AUTOSAR XML (schema 4-2-2)
package /STELLANTIS/EPT/SASWCs
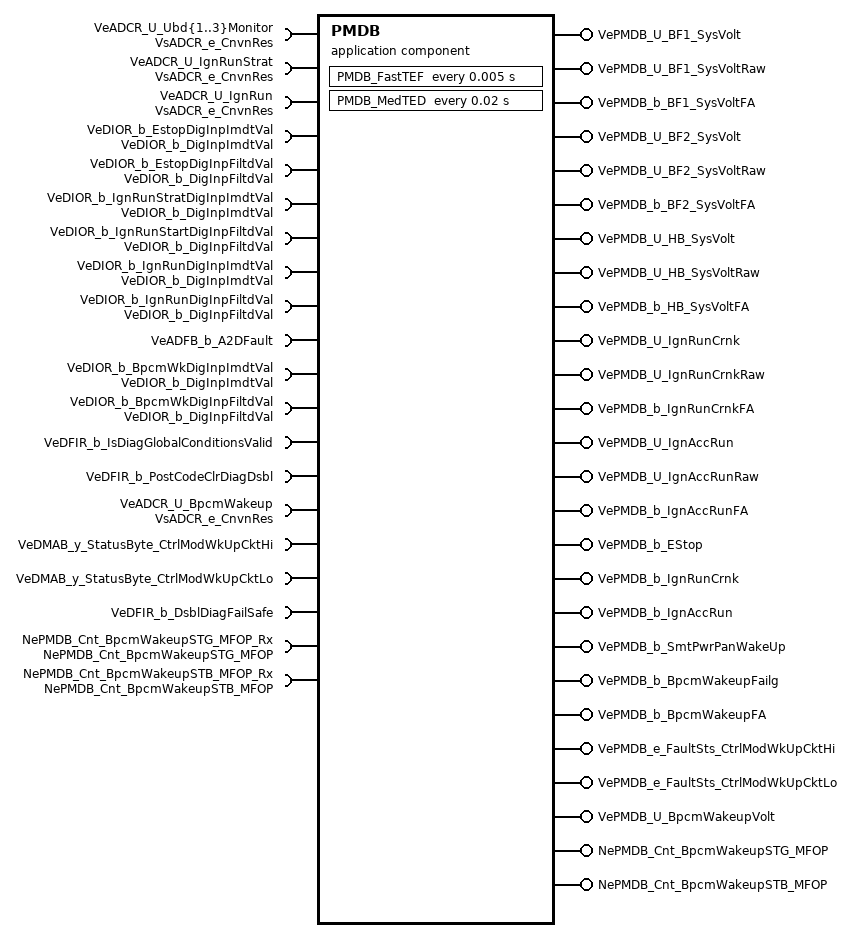
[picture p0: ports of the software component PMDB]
  application sw component type PMDB
    20 x require port:
      VeADCR_U_Ubd{1..3}Monitor: variation-point={short-label=vpVeADCR_U_Ubd{1..3}Monitor, sw-syscond=1}, nonqueued-receiver-com-spec{data-element=VsADCR_e_CnvnRes, init-value={short-label=DefaultInitValue_IDTRAdcInpResData, fields=[0, 0]}}, required-interface=VsADCR_e_CnvnRes
      VeADCR_U_IgnRunStrat: variation-point={short-label=vpVeADCR_U_IgnRunStrat, sw-syscond=1}, nonqueued-receiver-com-spec{data-element=VsADCR_e_CnvnRes, init-value={short-label=DefaultInitValue_IDTRAdcInpResData, fields=[0, 0]}}, required-interface=VsADCR_e_CnvnRes
      VeADCR_U_IgnRun: variation-point={short-label=vpVeADCR_U_IgnRun, sw-syscond=1}, nonqueued-receiver-com-spec{data-element=VsADCR_e_CnvnRes, init-value={short-label=DefaultInitValue_IDTRAdcInpResData, fields=[0, 0]}}, required-interface=VsADCR_e_CnvnRes
      VeDIOR_b_EstopDigInpImdtVal: variation-point={short-label=vpVeDIOR_b_EstopDigInpImdtVal, sw-syscond=1}, nonqueued-receiver-com-spec{data-element=VeDIOR_b_DigInpImdtVal, init-value=0}, required-interface=VeDIOR_b_DigInpImdtVal
      VeDIOR_b_EstopDigInpFiltdVal: variation-point={short-label=vpVeDIOR_b_EstopDigInpFiltdVal, sw-syscond=1}, nonqueued-receiver-com-spec{data-element=VeDIOR_b_DigInpFiltdVal, init-value=0}, required-interface=VeDIOR_b_DigInpFiltdVal
      VeDIOR_b_IgnRunStratDigInpImdtVal: variation-point={short-label=vpVeDIOR_b_IgnRunStratDigInpImdtVal, sw-syscond=1}, nonqueued-receiver-com-spec{data-element=VeDIOR_b_DigInpImdtVal, init-value=0}, required-interface=VeDIOR_b_DigInpImdtVal
      VeDIOR_b_IgnRunStartDigInpFiltdVal: variation-point={short-label=vpVeDIOR_b_IgnRunStartDigInpFiltdVal, sw-syscond=1}, nonqueued-receiver-com-spec{data-element=VeDIOR_b_DigInpFiltdVal, init-value=0}, required-interface=VeDIOR_b_DigInpFiltdVal
      VeDIOR_b_IgnRunDigInpImdtVal: variation-point={short-label=vpVeDIOR_b_IgnRunDigInpImdtVal, sw-syscond=1}, nonqueued-receiver-com-spec{data-element=VeDIOR_b_DigInpImdtVal, init-value=0}, required-interface=VeDIOR_b_DigInpImdtVal
      VeDIOR_b_IgnRunDigInpFiltdVal: variation-point={short-label=vpVeDIOR_b_IgnRunDigInpFiltdVal, sw-syscond=1}, nonqueued-receiver-com-spec{data-element=VeDIOR_b_DigInpFiltdVal, init-value=0}, required-interface=VeDIOR_b_DigInpFiltdVal
      VeADFB_b_A2DFault: variation-point={short-label=vpVeADFB_b_A2DFault, sw-syscond=1}, nonqueued-receiver-com-spec{data-element=Value, init-value=0}, required-interface=VeADFB_b_A2DFault
      VeDIOR_b_BpcmWkDigInpImdtVal: variation-point={short-label=vpVeDIOR_b_BpcmWkDigInpImdtVal, sw-syscond=1}, nonqueued-receiver-com-spec{data-element=VeDIOR_b_DigInpImdtVal, init-value=0}, required-interface=VeDIOR_b_DigInpImdtVal
      VeDIOR_b_BpcmWkDigInpFiltdVal: variation-point={short-label=vpVeDIOR_b_BpcmWkDigInpFiltdVal, sw-syscond=1}, nonqueued-receiver-com-spec{data-element=VeDIOR_b_DigInpFiltdVal, init-value=0}, required-interface=VeDIOR_b_DigInpFiltdVal
      VeDFIR_b_IsDiagGlobalConditionsValid: variation-point={short-label=vpVeDFIR_b_IsDiagGlobalConditionsValid, sw-syscond=1}, nonqueued-receiver-com-spec{data-element=Value, init-value=0}, required-interface=VeDFIR_b_IsDiagGlobalConditionsValid
      VeDFIR_b_PostCodeClrDiagDsbl: variation-point={short-label=vpVeDFIR_b_PostCodeClrDiagDsbl, sw-syscond=1}, nonqueued-receiver-com-spec{data-element=Value, init-value=0}, required-interface=VeDFIR_b_PostCodeClrDiagDsbl
      VeADCR_U_BpcmWakeup: variation-point={short-label=vpVeADCR_U_BpcmWakeup, sw-syscond=1}, nonqueued-receiver-com-spec{data-element=VsADCR_e_CnvnRes, init-value={short-label=DefaultInitValue_IDTRAdcInpResData, fields=[0, 0]}}, required-interface=VsADCR_e_CnvnRes
      VeDMAB_y_StatusByte_CtrlModWkUpCktHi: variation-point={short-label=vpVeDMAB_y_StatusByte_CtrlModWkUpCktHi, sw-syscond=1}, nonqueued-receiver-com-spec{data-element=Value, init-value=0}, required-interface=VeDMAB_y_StatusByte_CtrlModWkUpCktHi
      VeDMAB_y_StatusByte_CtrlModWkUpCktLo: variation-point={short-label=vpVeDMAB_y_StatusByte_CtrlModWkUpCktLo, sw-syscond=1}, nonqueued-receiver-com-spec{data-element=Value, init-value=0}, required-interface=VeDMAB_y_StatusByte_CtrlModWkUpCktLo
      VeDFIR_b_DsblDiagFailSafe: variation-point={short-label=vpVeDFIR_b_DsblDiagFailSafe, sw-syscond=1}, nonqueued-receiver-com-spec{data-element=Value, init-value=0}, required-interface=VeDFIR_b_DsblDiagFailSafe
    24 x provide port:
      VePMDB_U_BF1_SysVolt: variation-point={short-label=vpVePMDB_U_BF1_SysVolt, sw-syscond=1}, nonqueued-sender-com-spec{data-element=Value, init-value=0}, provided-interface=VePMDB_U_BF1_SysVolt
      VePMDB_U_BF1_SysVoltRaw: variation-point={short-label=vpVePMDB_U_BF1_SysVoltRaw, sw-syscond=1}, nonqueued-sender-com-spec{data-element=Value, init-value=0}, provided-interface=VePMDB_U_BF1_SysVoltRaw
      VePMDB_b_BF1_SysVoltFA: variation-point={short-label=vpVePMDB_b_BF1_SysVoltFA, sw-syscond=1}, nonqueued-sender-com-spec{data-element=Value, init-value=0}, provided-interface=VePMDB_b_BF1_SysVoltFA
      VePMDB_U_BF2_SysVolt: variation-point={short-label=vpVePMDB_U_BF2_SysVolt, sw-syscond=1}, nonqueued-sender-com-spec{data-element=Value, init-value=0}, provided-interface=VePMDB_U_BF2_SysVolt
      VePMDB_U_BF2_SysVoltRaw: variation-point={short-label=vpVePMDB_U_BF2_SysVoltRaw, sw-syscond=1}, nonqueued-sender-com-spec{data-element=Value, init-value=0}, provided-interface=VePMDB_U_BF2_SysVoltRaw
      VePMDB_b_BF2_SysVoltFA: variation-point={short-label=vpVePMDB_b_BF2_SysVoltFA, sw-syscond=1}, nonqueued-sender-com-spec{data-element=Value, init-value=0}, provided-interface=VePMDB_b_BF2_SysVoltFA
      VePMDB_U_HB_SysVolt: variation-point={short-label=vpVePMDB_U_HB_SysVolt, sw-syscond=1}, nonqueued-sender-com-spec{data-element=Value, init-value=0}, provided-interface=VePMDB_U_HB_SysVolt
      VePMDB_U_HB_SysVoltRaw: variation-point={short-label=vpVePMDB_U_HB_SysVoltRaw, sw-syscond=1}, nonqueued-sender-com-spec{data-element=Value, init-value=0}, provided-interface=VePMDB_U_HB_SysVoltRaw
      VePMDB_b_HB_SysVoltFA: variation-point={short-label=vpVePMDB_b_HB_SysVoltFA, sw-syscond=1}, nonqueued-sender-com-spec{data-element=Value, init-value=0}, provided-interface=VePMDB_b_HB_SysVoltFA
      VePMDB_U_IgnRunCrnk: variation-point={short-label=vpVePMDB_U_IgnRunCrnk, sw-syscond=1}, nonqueued-sender-com-spec{data-element=Value, init-value=0}, provided-interface=VePMDB_U_IgnRunCrnk
      VePMDB_U_IgnRunCrnkRaw: variation-point={short-label=vpVePMDB_U_IgnRunCrnkRaw, sw-syscond=1}, nonqueued-sender-com-spec{data-element=Value, init-value=0}, provided-interface=VePMDB_U_IgnRunCrnkRaw
      VePMDB_b_IgnRunCrnkFA: variation-point={short-label=vpVePMDB_b_IgnRunCrnkFA, sw-syscond=1}, nonqueued-sender-com-spec{data-element=Value, init-value=0}, provided-interface=VePMDB_b_IgnRunCrnkFA
      VePMDB_U_IgnAccRun: variation-point={short-label=vpVePMDB_U_IgnAccRun, sw-syscond=1}, nonqueued-sender-com-spec{data-element=Value, init-value=0}, provided-interface=VePMDB_U_IgnAccRun
      VePMDB_U_IgnAccRunRaw: variation-point={short-label=vpVePMDB_U_IgnAccRunRaw, sw-syscond=1}, nonqueued-sender-com-spec{data-element=Value, init-value=0}, provided-interface=VePMDB_U_IgnAccRunRaw
      VePMDB_b_IgnAccRunFA: variation-point={short-label=vpVePMDB_b_IgnAccRunFA, sw-syscond=1}, nonqueued-sender-com-spec{data-element=Value, init-value=0}, provided-interface=VePMDB_b_IgnAccRunFA
      VePMDB_b_EStop: variation-point={short-label=vpVePMDB_b_EStop, sw-syscond=1}, nonqueued-sender-com-spec{data-element=Value, init-value=0}, provided-interface=VePMDB_b_EStop
      VePMDB_b_IgnRunCrnk: variation-point={short-label=vpVePMDB_b_IgnRunCrnk, sw-syscond=1}, nonqueued-sender-com-spec{data-element=Value, init-value=0}, provided-interface=VePMDB_b_IgnRunCrnk
      VePMDB_b_IgnAccRun: variation-point={short-label=vpVePMDB_b_IgnAccRun, sw-syscond=1}, nonqueued-sender-com-spec{data-element=Value, init-value=0}, provided-interface=VePMDB_b_IgnAccRun
      VePMDB_b_SmtPwrPanWakeUp: variation-point={short-label=vpVePMDB_b_SmtPwrPanWakeUp, sw-syscond=1}, nonqueued-sender-com-spec{data-element=Value, init-value=0}, provided-interface=VePMDB_b_SmtPwrPanWakeUp
      VePMDB_b_BpcmWakeupFailg: variation-point={short-label=vpVePMDB_b_BpcmWakeupFailg, sw-syscond=1}, nonqueued-sender-com-spec{data-element=Value, init-value=0}, provided-interface=VePMDB_b_BpcmWakeupFailg
      VePMDB_b_BpcmWakeupFA: variation-point={short-label=vpVePMDB_b_BpcmWakeupFA, sw-syscond=1}, nonqueued-sender-com-spec{data-element=Value, init-value=0}, provided-interface=VePMDB_b_BpcmWakeupFA
      VePMDB_e_FaultSts_CtrlModWkUpCktHi: variation-point={short-label=vpVePMDB_e_FaultSts_CtrlModWkUpCktHi, sw-syscond=1}, nonqueued-sender-com-spec{data-element=Value, init-value=CeDFIB_e_Init}, provided-interface=VePMDB_e_FaultSts_CtrlModWkUpCktHi
      VePMDB_e_FaultSts_CtrlModWkUpCktLo: variation-point={short-label=vpVePMDB_e_FaultSts_CtrlModWkUpCktLo, sw-syscond=1}, nonqueued-sender-com-spec{data-element=Value, init-value=CeDFIB_e_Init}, provided-interface=VePMDB_e_FaultSts_CtrlModWkUpCktLo
      VePMDB_U_BpcmWakeupVolt: variation-point={short-label=vpVePMDB_U_BpcmWakeupVolt, sw-syscond=1}, nonqueued-sender-com-spec{data-element=Value, init-value=0}, provided-interface=VePMDB_U_BpcmWakeupVolt
    require port NePMDB_Cnt_BpcmWakeupSTG_MFOP_Rx: variation-point={short-label=vpNePMDB_Cnt_BpcmWakeupSTG_MFOP_Rx, sw-syscond=1}, nv-require-com-spec{init-value=0, variable=NePMDB_Cnt_BpcmWakeupSTG_MFOP}, required-interface=NePMDB_Cnt_BpcmWakeupSTG_MFOP
    require port NePMDB_Cnt_BpcmWakeupSTB_MFOP_Rx: variation-point={short-label=vpNePMDB_Cnt_BpcmWakeupSTB_MFOP_Rx, sw-syscond=1}, nv-require-com-spec{init-value=0, variable=NePMDB_Cnt_BpcmWakeupSTB_MFOP}, required-interface=NePMDB_Cnt_BpcmWakeupSTB_MFOP
    provide port NePMDB_Cnt_BpcmWakeupSTG_MFOP: nv-provide-com-spec{ram-block-init-value=0, variable=NePMDB_Cnt_BpcmWakeupSTG_MFOP}, provided-interface=NePMDB_Cnt_BpcmWakeupSTG_MFOP
    provide port NePMDB_Cnt_BpcmWakeupSTB_MFOP: nv-provide-com-spec{ram-block-init-value=0, variable=NePMDB_Cnt_BpcmWakeupSTB_MFOP}, provided-interface=NePMDB_Cnt_BpcmWakeupSTB_MFOP
    behavior IB_PMDB: data-type-mapping=[msADTtoIDTMapping, ADTtoIDTMapping], handle-termination-and-restart=NO-SUPPORT
      timing event Event_FastTEF: start-on-event=PMDB_FastTEF, period=0.005
      timing event Event_MedTED: start-on-event=PMDB_MedTED, period=0.02
      init event Event_PMDB_ac_Init: start-on-event=PMDB_ac_Init
      init event Event_PwrOff: start-on-event=PMDB_PwrOff
      4 x runnable:
        PMDB_ac_Init
          data-receive-point-by-arguments:
            access IN_NePMDB_Cnt_BpcmWakeupSTB_MFOP_Rx_NePMDB_Cnt_BpcmWakeupSTB_MFOP: accessed-variable=NePMDB_Cnt_BpcmWakeupSTB_MFOP_Rx.NePMDB_Cnt_BpcmWakeupSTB_MFOP, variation-point={short-label=vpIN_NePMDB_Cnt_BpcmWakeupSTB_MFOP_Rx_NePMDB_Cnt_BpcmWakeupSTB_MFOP, sw-syscond=1}
            access IN_NePMDB_Cnt_BpcmWakeupSTG_MFOP_Rx_NePMDB_Cnt_BpcmWakeupSTG_MFOP: accessed-variable=NePMDB_Cnt_BpcmWakeupSTG_MFOP_Rx.NePMDB_Cnt_BpcmWakeupSTG_MFOP, variation-point={short-label=vpIN_NePMDB_Cnt_BpcmWakeupSTG_MFOP_Rx_NePMDB_Cnt_BpcmWakeupSTG_MFOP, sw-syscond=1}
          data-send-points:
            19 x access:
              OUT_VePMDB_U_BF1_SysVolt_Value: accessed-variable=VePMDB_U_BF1_SysVolt.Value, variation-point={short-label=vpOUT_VePMDB_U_BF1_SysVolt_Value, sw-syscond=1}
              OUT_VePMDB_U_BF1_SysVoltRaw_Value: accessed-variable=VePMDB_U_BF1_SysVoltRaw.Value, variation-point={short-label=vpOUT_VePMDB_U_BF1_SysVoltRaw_Value, sw-syscond=1}
              OUT_VePMDB_U_BF2_SysVolt_Value: accessed-variable=VePMDB_U_BF2_SysVolt.Value, variation-point={short-label=vpOUT_VePMDB_U_BF2_SysVolt_Value, sw-syscond=1}
              OUT_VePMDB_U_BF2_SysVoltRaw_Value: accessed-variable=VePMDB_U_BF2_SysVoltRaw.Value, variation-point={short-label=vpOUT_VePMDB_U_BF2_SysVoltRaw_Value, sw-syscond=1}
              OUT_VePMDB_U_HB_SysVolt_Value: accessed-variable=VePMDB_U_HB_SysVolt.Value, variation-point={short-label=vpOUT_VePMDB_U_HB_SysVolt_Value, sw-syscond=1}
              OUT_VePMDB_U_HB_SysVoltRaw_Value: accessed-variable=VePMDB_U_HB_SysVoltRaw.Value, variation-point={short-label=vpOUT_VePMDB_U_HB_SysVoltRaw_Value, sw-syscond=1}
              OUT_VePMDB_U_IgnRunCrnk_Value: accessed-variable=VePMDB_U_IgnRunCrnk.Value, variation-point={short-label=vpOUT_VePMDB_U_IgnRunCrnk_Value, sw-syscond=1}
              OUT_VePMDB_U_IgnRunCrnkRaw_Value: accessed-variable=VePMDB_U_IgnRunCrnkRaw.Value, variation-point={short-label=vpOUT_VePMDB_U_IgnRunCrnkRaw_Value, sw-syscond=1}
              OUT_VePMDB_U_IgnAccRun_Value: accessed-variable=VePMDB_U_IgnAccRun.Value, variation-point={short-label=vpOUT_VePMDB_U_IgnAccRun_Value, sw-syscond=1}
              OUT_VePMDB_U_IgnAccRunRaw_Value: accessed-variable=VePMDB_U_IgnAccRunRaw.Value, variation-point={short-label=vpOUT_VePMDB_U_IgnAccRunRaw_Value, sw-syscond=1}
              OUT_VePMDB_b_EStop_Value: accessed-variable=VePMDB_b_EStop.Value, variation-point={short-label=vpOUT_VePMDB_b_EStop_Value, sw-syscond=1}
              OUT_VePMDB_b_IgnRunCrnk_Value: accessed-variable=VePMDB_b_IgnRunCrnk.Value, variation-point={short-label=vpOUT_VePMDB_b_IgnRunCrnk_Value, sw-syscond=1}
              OUT_VePMDB_b_IgnAccRun_Value: accessed-variable=VePMDB_b_IgnAccRun.Value, variation-point={short-label=vpOUT_VePMDB_b_IgnAccRun_Value, sw-syscond=1}
              OUT_VePMDB_b_SmtPwrPanWakeUp_Value: accessed-variable=VePMDB_b_SmtPwrPanWakeUp.Value, variation-point={short-label=vpOUT_VePMDB_b_SmtPwrPanWakeUp_Value, sw-syscond=1}
              OUT_VePMDB_b_BpcmWakeupFailg_Value: accessed-variable=VePMDB_b_BpcmWakeupFailg.Value, variation-point={short-label=vpOUT_VePMDB_b_BpcmWakeupFailg_Value, sw-syscond=1}
              OUT_VePMDB_b_BpcmWakeupFA_Value: accessed-variable=VePMDB_b_BpcmWakeupFA.Value, variation-point={short-label=vpOUT_VePMDB_b_BpcmWakeupFA_Value, sw-syscond=1}
              OUT_VePMDB_e_FaultSts_CtrlModWkUpCktHi_Value: accessed-variable=VePMDB_e_FaultSts_CtrlModWkUpCktHi.Value, variation-point={short-label=vpOUT_VePMDB_e_FaultSts_CtrlModWkUpCktHi_Value, sw-syscond=1}
              OUT_VePMDB_e_FaultSts_CtrlModWkUpCktLo_Value: accessed-variable=VePMDB_e_FaultSts_CtrlModWkUpCktLo.Value, variation-point={short-label=vpOUT_VePMDB_e_FaultSts_CtrlModWkUpCktLo_Value, sw-syscond=1}
              OUT_VePMDB_U_BpcmWakeupVolt_Value: accessed-variable=VePMDB_U_BpcmWakeupVolt.Value, variation-point={short-label=vpOUT_VePMDB_U_BpcmWakeupVolt_Value, sw-syscond=1}
        PMDB_FastTEF
          data-receive-point-by-arguments:
            20 x access:
              IN_VeADCR_U_BpcmWakeup_VsADCR_e_CnvnRes: accessed-variable=VeADCR_U_BpcmWakeup.VsADCR_e_CnvnRes, variation-point={short-label=vpIN_VeADCR_U_BpcmWakeup_VsADCR_e_CnvnRes, sw-syscond=1}
              IN_VeADCR_U_IgnRunStrat_VsADCR_e_CnvnRes: accessed-variable=VeADCR_U_IgnRunStrat.VsADCR_e_CnvnRes, variation-point={short-label=vpIN_VeADCR_U_IgnRunStrat_VsADCR_e_CnvnRes, sw-syscond=1}
              IN_VeADCR_U_IgnRun_VsADCR_e_CnvnRes: accessed-variable=VeADCR_U_IgnRun.VsADCR_e_CnvnRes, variation-point={short-label=vpIN_VeADCR_U_IgnRun_VsADCR_e_CnvnRes, sw-syscond=1}
              IN_VeADCR_U_Ubd{1..3}Monitor_VsADCR_e_CnvnRes: accessed-variable=VeADCR_U_Ubd{1..3}Monitor.VsADCR_e_CnvnRes, variation-point={short-label=vpIN_VeADCR_U_Ubd{1..3}Monitor_VsADCR_e_CnvnRes, sw-syscond=1}
              IN_VeADFB_b_A2DFault_Value: accessed-variable=VeADFB_b_A2DFault.Value, variation-point={short-label=vpIN_VeADFB_b_A2DFault_Value, sw-syscond=1}
              IN_VeDFIR_b_DsblDiagFailSafe_Value: accessed-variable=VeDFIR_b_DsblDiagFailSafe.Value, variation-point={short-label=vpIN_VeDFIR_b_DsblDiagFailSafe_Value, sw-syscond=1}
              IN_VeDFIR_b_IsDiagGlobalConditionsValid_Value: accessed-variable=VeDFIR_b_IsDiagGlobalConditionsValid.Value, variation-point={short-label=vpIN_VeDFIR_b_IsDiagGlobalConditionsValid_Value, sw-syscond=1}
              IN_VeDFIR_b_PostCodeClrDiagDsbl_Value: accessed-variable=VeDFIR_b_PostCodeClrDiagDsbl.Value, variation-point={short-label=vpIN_VeDFIR_b_PostCodeClrDiagDsbl_Value, sw-syscond=1}
              IN_VeDIOR_b_BpcmWkDigInpFiltdVal_VeDIOR_b_DigInpFiltdVal: accessed-variable=VeDIOR_b_BpcmWkDigInpFiltdVal.VeDIOR_b_DigInpFiltdVal, variation-point={short-label=vpIN_VeDIOR_b_BpcmWkDigInpFiltdVal_VeDIOR_b_DigInpFiltdVal, sw-syscond=1}
              IN_VeDIOR_b_BpcmWkDigInpImdtVal_VeDIOR_b_DigInpImdtVal: accessed-variable=VeDIOR_b_BpcmWkDigInpImdtVal.VeDIOR_b_DigInpImdtVal, variation-point={short-label=vpIN_VeDIOR_b_BpcmWkDigInpImdtVal_VeDIOR_b_DigInpImdtVal, sw-syscond=1}
              IN_VeDIOR_b_EstopDigInpFiltdVal_VeDIOR_b_DigInpFiltdVal: accessed-variable=VeDIOR_b_EstopDigInpFiltdVal.VeDIOR_b_DigInpFiltdVal, variation-point={short-label=vpIN_VeDIOR_b_EstopDigInpFiltdVal_VeDIOR_b_DigInpFiltdVal, sw-syscond=1}
              IN_VeDIOR_b_EstopDigInpImdtVal_VeDIOR_b_DigInpImdtVal: accessed-variable=VeDIOR_b_EstopDigInpImdtVal.VeDIOR_b_DigInpImdtVal, variation-point={short-label=vpIN_VeDIOR_b_EstopDigInpImdtVal_VeDIOR_b_DigInpImdtVal, sw-syscond=1}
              IN_VeDIOR_b_IgnRunDigInpFiltdVal_VeDIOR_b_DigInpFiltdVal: accessed-variable=VeDIOR_b_IgnRunDigInpFiltdVal.VeDIOR_b_DigInpFiltdVal, variation-point={short-label=vpIN_VeDIOR_b_IgnRunDigInpFiltdVal_VeDIOR_b_DigInpFiltdVal, sw-syscond=1}
              IN_VeDIOR_b_IgnRunDigInpImdtVal_VeDIOR_b_DigInpImdtVal: accessed-variable=VeDIOR_b_IgnRunDigInpImdtVal.VeDIOR_b_DigInpImdtVal, variation-point={short-label=vpIN_VeDIOR_b_IgnRunDigInpImdtVal_VeDIOR_b_DigInpImdtVal, sw-syscond=1}
              IN_VeDIOR_b_IgnRunStartDigInpFiltdVal_VeDIOR_b_DigInpFiltdVal: accessed-variable=VeDIOR_b_IgnRunStartDigInpFiltdVal.VeDIOR_b_DigInpFiltdVal, variation-point={short-label=vpIN_VeDIOR_b_IgnRunStartDigInpFiltdVal_VeDIOR_b_DigInpFiltdVal, sw-syscond=1}
              IN_VeDIOR_b_IgnRunStratDigInpImdtVal_VeDIOR_b_DigInpImdtVal: accessed-variable=VeDIOR_b_IgnRunStratDigInpImdtVal.VeDIOR_b_DigInpImdtVal, variation-point={short-label=vpIN_VeDIOR_b_IgnRunStratDigInpImdtVal_VeDIOR_b_DigInpImdtVal, sw-syscond=1}
              IN_VeDMAB_y_StatusByte_CtrlModWkUpCktHi_Value: accessed-variable=VeDMAB_y_StatusByte_CtrlModWkUpCktHi.Value, variation-point={short-label=vpIN_VeDMAB_y_StatusByte_CtrlModWkUpCktHi_Value, sw-syscond=1}
              IN_VeDMAB_y_StatusByte_CtrlModWkUpCktLo_Value: accessed-variable=VeDMAB_y_StatusByte_CtrlModWkUpCktLo.Value, variation-point={short-label=vpIN_VeDMAB_y_StatusByte_CtrlModWkUpCktLo_Value, sw-syscond=1}
          data-send-points:
            24 x access:
              OUT_VePMDB_U_BF1_SysVoltRaw_Value: accessed-variable=VePMDB_U_BF1_SysVoltRaw.Value, variation-point={short-label=vpOUT_VePMDB_U_BF1_SysVoltRaw_Value, sw-syscond=1}
              OUT_VePMDB_U_BF1_SysVolt_Value: accessed-variable=VePMDB_U_BF1_SysVolt.Value, variation-point={short-label=vpOUT_VePMDB_U_BF1_SysVolt_Value, sw-syscond=1}
              OUT_VePMDB_U_BF2_SysVoltRaw_Value: accessed-variable=VePMDB_U_BF2_SysVoltRaw.Value, variation-point={short-label=vpOUT_VePMDB_U_BF2_SysVoltRaw_Value, sw-syscond=1}
              OUT_VePMDB_U_BF2_SysVolt_Value: accessed-variable=VePMDB_U_BF2_SysVolt.Value, variation-point={short-label=vpOUT_VePMDB_U_BF2_SysVolt_Value, sw-syscond=1}
              OUT_VePMDB_U_HB_SysVoltRaw_Value: accessed-variable=VePMDB_U_HB_SysVoltRaw.Value, variation-point={short-label=vpOUT_VePMDB_U_HB_SysVoltRaw_Value, sw-syscond=1}
              OUT_VePMDB_U_HB_SysVolt_Value: accessed-variable=VePMDB_U_HB_SysVolt.Value, variation-point={short-label=vpOUT_VePMDB_U_HB_SysVolt_Value, sw-syscond=1}
              OUT_VePMDB_U_IgnRunCrnkRaw_Value: accessed-variable=VePMDB_U_IgnRunCrnkRaw.Value, variation-point={short-label=vpOUT_VePMDB_U_IgnRunCrnkRaw_Value, sw-syscond=1}
              OUT_VePMDB_U_IgnRunCrnk_Value: accessed-variable=VePMDB_U_IgnRunCrnk.Value, variation-point={short-label=vpOUT_VePMDB_U_IgnRunCrnk_Value, sw-syscond=1}
              OUT_VePMDB_U_IgnAccRunRaw_Value: accessed-variable=VePMDB_U_IgnAccRunRaw.Value, variation-point={short-label=vpOUT_VePMDB_U_IgnAccRunRaw_Value, sw-syscond=1}
              OUT_VePMDB_U_IgnAccRun_Value: accessed-variable=VePMDB_U_IgnAccRun.Value, variation-point={short-label=vpOUT_VePMDB_U_IgnAccRun_Value, sw-syscond=1}
              OUT_VePMDB_b_IgnAccRun_Value: accessed-variable=VePMDB_b_IgnAccRun.Value, variation-point={short-label=vpOUT_VePMDB_b_IgnAccRun_Value, sw-syscond=1}
              OUT_VePMDB_b_BF1_SysVoltFA_Value: accessed-variable=VePMDB_b_BF1_SysVoltFA.Value, variation-point={short-label=vpOUT_VePMDB_b_BF1_SysVoltFA_Value, sw-syscond=1}
              OUT_VePMDB_b_BF2_SysVoltFA_Value: accessed-variable=VePMDB_b_BF2_SysVoltFA.Value, variation-point={short-label=vpOUT_VePMDB_b_BF2_SysVoltFA_Value, sw-syscond=1}
              OUT_VePMDB_b_HB_SysVoltFA_Value: accessed-variable=VePMDB_b_HB_SysVoltFA.Value, variation-point={short-label=vpOUT_VePMDB_b_HB_SysVoltFA_Value, sw-syscond=1}
              OUT_VePMDB_b_IgnRunCrnkFA_Value: accessed-variable=VePMDB_b_IgnRunCrnkFA.Value, variation-point={short-label=vpOUT_VePMDB_b_IgnRunCrnkFA_Value, sw-syscond=1}
              OUT_VePMDB_b_IgnAccRunFA_Value: accessed-variable=VePMDB_b_IgnAccRunFA.Value, variation-point={short-label=vpOUT_VePMDB_b_IgnAccRunFA_Value, sw-syscond=1}
              OUT_VePMDB_b_SmtPwrPanWakeUp_Value: accessed-variable=VePMDB_b_SmtPwrPanWakeUp.Value, variation-point={short-label=vpOUT_VePMDB_b_SmtPwrPanWakeUp_Value, sw-syscond=1}
              OUT_VePMDB_b_BpcmWakeupFA_Value: accessed-variable=VePMDB_b_BpcmWakeupFA.Value, variation-point={short-label=vpOUT_VePMDB_b_BpcmWakeupFA_Value, sw-syscond=1}
              OUT_VePMDB_e_FaultSts_CtrlModWkUpCktHi_Value: accessed-variable=VePMDB_e_FaultSts_CtrlModWkUpCktHi.Value, variation-point={short-label=vpOUT_VePMDB_e_FaultSts_CtrlModWkUpCktHi_Value, sw-syscond=1}
              OUT_VePMDB_e_FaultSts_CtrlModWkUpCktLo_Value: accessed-variable=VePMDB_e_FaultSts_CtrlModWkUpCktLo.Value, variation-point={short-label=vpOUT_VePMDB_e_FaultSts_CtrlModWkUpCktLo_Value, sw-syscond=1}
              OUT_VePMDB_b_IgnRunCrnk_Value: accessed-variable=VePMDB_b_IgnRunCrnk.Value, variation-point={short-label=vpOUT_VePMDB_b_IgnRunCrnk_Value, sw-syscond=1}
              OUT_VePMDB_b_EStop_Value: accessed-variable=VePMDB_b_EStop.Value, variation-point={short-label=vpOUT_VePMDB_b_EStop_Value, sw-syscond=1}
              OUT_VePMDB_b_BpcmWakeupFailg_Value: accessed-variable=VePMDB_b_BpcmWakeupFailg.Value, variation-point={short-label=vpOUT_VePMDB_b_BpcmWakeupFailg_Value, sw-syscond=1}
              OUT_VePMDB_U_BpcmWakeupVolt_Value: accessed-variable=VePMDB_U_BpcmWakeupVolt.Value, variation-point={short-label=vpOUT_VePMDB_U_BpcmWakeupVolt_Value, sw-syscond=1}
        PMDB_MedTED
          data-receive-point-by-arguments:
            access IN_VeADFB_b_A2DFault_Value: accessed-variable=VeADFB_b_A2DFault.Value, variation-point={short-label=vpIN_VeADFB_b_A2DFault_Value, sw-syscond=1}
        PMDB_PwrOff
          data-send-points:
            access OUT_NePMDB_Cnt_BpcmWakeupSTG_MFOP_NePMDB_Cnt_BpcmWakeupSTG_MFOP: accessed-variable=NePMDB_Cnt_BpcmWakeupSTG_MFOP.NePMDB_Cnt_BpcmWakeupSTG_MFOP
            access OUT_NePMDB_Cnt_BpcmWakeupSTB_MFOP_NePMDB_Cnt_BpcmWakeupSTB_MFOP: accessed-variable=NePMDB_Cnt_BpcmWakeupSTB_MFOP.NePMDB_Cnt_BpcmWakeupSTB_MFOP
      12 x variation point proxy, all with category=CONDITION:
        Variant_PMDB_BF1_Presence: condition-access=1
        Variant_PMDB_BF2_Presence: condition-access=1
        Variant_PMDB_BPCMWup_Presence: condition-access=1
        Variant_PMDB_ESTOP_Presence: condition-access=1
        Variant_PMDB_HB_Presence: condition-access=1
        Variant_PMDB_IGNACCDIG_Presence: condition-access=1
        Variant_PMDB_IGNACC_Presence: condition-access=1
        Variant_PMDB_IGNRUNDIG_Presence: condition-access=1
        Variant_PMDB_IGNRUN_Presence: condition-access=1
        Variant_PMDB_OBCMWup_Presence: condition-access=0
        Variant_PMDB_PCUPURDF_Presence: condition-access=0
        Variant_PMDB_PWRPanel_Presence: condition-access=0
